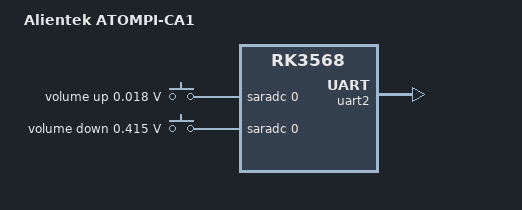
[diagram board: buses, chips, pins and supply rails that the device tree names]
/*
 * SPDX-License-Identifier:     GPL-2.0+
 *
 * (C) Copyright 2020 Rockchip Electronics Co., Ltd
 */

/dts-v1/;
#include "rk3568.dtsi"
#include "rk356x-u-boot.dtsi"
#include <dt-bindings/input/input.h>

/ {
	model = "Alientek ATOMPI-CA1";
	compatible = "alientek,atompi-ca1", "rockchip,rk3568";

	adc-keys {
		compatible = "adc-keys";
		io-channels = <&saradc 0>;
		io-channel-names = "buttons";
		keyup-threshold-microvolt = <1800000>;
		u-boot,dm-spl;
		status = "okay";

		volumeup-key {
			u-boot,dm-spl;
			linux,code = <KEY_VOLUMEUP>;
			label = "volume up";
			press-threshold-microvolt = <17822>;
		};

		volumedown-key {
			u-boot,dm-spl;
			label = "volume down";
			linux,code = <KEY_VOLUMEDOWN>;
			press-threshold-microvolt = <415385>;
		};
	};
};

&uart2 {
	status = "okay";
};
